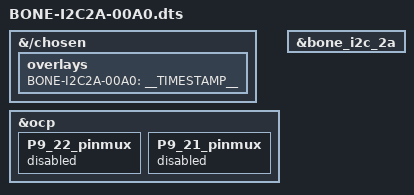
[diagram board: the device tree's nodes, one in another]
/*
 * Copyright (C) 2020 Deepak Khatri <deepaklorkhatri7@gmail.com>
 *
 * Virtual cape for /bone/i2c/2a (only on BBB)
 *
 * Note: This can not be used along with BONE-I2C2-00A0 on BBB as 
 * both uses i2c2 internally and only one can be used at a time.
 * you have to edit the bbb-bone-buses.dtsi file to enable this!
 *
 * This program is free software; you can redistribute it and/or modify
 * it under the terms of the GNU General Public License version 2 as
 * published by the Free Software Foundation.
 */
 
/dts-v1/;
/plugin/;

/*
* Helper to show loaded overlays under: /proc/device-tree/chosen/overlays/
*/
&{/chosen} {
    overlays {
        BONE-I2C2A-00A0 = __TIMESTAMP__;
    };
};

/*
* Free up the pins used by the cape from the pinmux helpers.
*/
&ocp {
    P9_22_pinmux { status = "disabled"; };
    P9_21_pinmux { status = "disabled"; };
};

&bone_i2c_2a {
    // See these files for the definition
    // https://github.com/beagleboard/BeagleBoard-DeviceTrees/src/arm/bbai-bone-buses.dtsi
    // https://github.com/beagleboard/BeagleBoard-DeviceTrees/src/arm/bbb-bone-buses.dtsi
    status = "okay";
};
